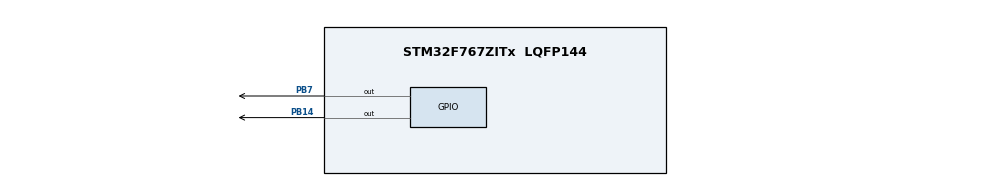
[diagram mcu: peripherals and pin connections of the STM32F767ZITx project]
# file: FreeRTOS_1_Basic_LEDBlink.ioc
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FREERTOS.Tasks01=blinkLEDBlue,24,128,StartBlinkLEDBlue,Default,NULL,Dynamic,NULL,NULL;blinkLEDRed,16,128,StartBlinkLEDRed,Default,NULL,Dynamic,NULL,NULL
Mcu.Family=STM32F7
Mcu.Name=STM32F767ZITx
Mcu.Package=LQFP144
NVIC.PriorityGroup=NVIC_PRIORITYGROUP_4
NVIC.TIM2_IRQn=true\:15\:0\:false\:false\:true\:false\:false\:true\:true
NVIC.TimeBase=TIM2_IRQn
NVIC.TimeBaseIP=TIM2
PA13.Mode=Serial_Wire
PA13.Signal=SYS_JTMS-SWDIO
PA14.Mode=Serial_Wire
PA14.Signal=SYS_JTCK-SWCLK
PB14.Signal=GPIO_Output
PB7.Signal=GPIO_Output
ProjectManager.HeapSize=0x200
ProjectManager.StackSize=0x400
ProjectManager.TargetToolchain=CMake
RCC.HSE_VALUE=25000000
RCC.HSI_VALUE=16000000
RCC.LSE_VALUE=32768
RCC.USBFreq_Value=96000000
RCC.VCOOutputFreq_Value=192000000
VP_FREERTOS_VS_CMSIS_V2.Mode=CMSIS_V2
VP_SYS_VS_tim2.Mode=TIM2
board=custom

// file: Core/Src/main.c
/* USER CODE BEGIN Header */
/**
  * @file           : main.c
  * @brief          : Main program body
  ******************************************************************************
  * @author         : Jabed-Akhtar
  * @date           : 13.03.2022
  ******************************************************************************
  * Description:
  *		- LED: PB7(Blue) and PB14(Red) (for testing purpose)
  *		- freeRTOS:
  *			|- thread1: blinkLEDBlueHandle -> thread to blink BlueLED every 500ms
  *				-> task is programmed inside StartBlinkLEDBlue(void)
  *			|- thread2: blinkLEDRed -> thread to blink RedLED every 600ms
  *				-> task is programmed inside StartBlinkLEDRed(void)
  *******************************************************************************/

/* USER CODE END Header */
#include "main.h"
#include "cmsis_os.h"

/* Definitions for blinkLEDBlue */
osThreadId_t blinkLEDBlueHandle;
const osThreadAttr_t blinkLEDBlue_attributes = {
  .name = "blinkLEDBlue",
  .stack_size = 128 * 4,
  .priority = (osPriority_t) osPriorityNormal,
};
/* Definitions for blinkLEDRed */
osThreadId_t blinkLEDRedHandle;
const osThreadAttr_t blinkLEDRed_attributes = {
  .name = "blinkLEDRed",
  .stack_size = 128 * 4,
  .priority = (osPriority_t) osPriorityBelowNormal,
};

void SystemClock_Config(void);
static void MX_GPIO_Init(void);
void StartBlinkLEDBlue(void *argument);
void StartBlinkLEDRed(void *argument);

int main(void)
{

  /* MCU Configuration--------------------------------------------------------*/

  /* Reset of all peripherals, Initializes the Flash interface and the Systick. */
  HAL_Init();

  /* Configure the system clock */
  SystemClock_Config();

  /* Initialize all configured peripherals */
  MX_GPIO_Init();

  /* Init scheduler */
  osKernelInitialize();

  /* Create the thread(s) */
  /* creation of blinkLEDBlue */
  blinkLEDBlueHandle = osThreadNew(StartBlinkLEDBlue, NULL, &blinkLEDBlue_attributes);

  /* creation of blinkLEDRed */
  blinkLEDRedHandle = osThreadNew(StartBlinkLEDRed, NULL, &blinkLEDRed_attributes);

  /* Start scheduler */
  osKernelStart();

  /* We should never get here as control is now taken by the scheduler */

  /* Infinite loop */
  while (1)
  {

  }
}

void SystemClock_Config(void)
{
  RCC_OscInitTypeDef RCC_OscInitStruct = {0};
  RCC_ClkInitTypeDef RCC_ClkInitStruct = {0};

  /** Configure the main internal regulator output voltage
  */
  __HAL_RCC_PWR_CLK_ENABLE();
  __HAL_PWR_VOLTAGESCALING_CONFIG(PWR_REGULATOR_VOLTAGE_SCALE3);

  /** Initializes the RCC Oscillators according to the specified parameters
  * in the RCC_OscInitTypeDef structure.
  */
  RCC_OscInitStruct.OscillatorType = RCC_OSCILLATORTYPE_HSI;
  RCC_OscInitStruct.HSIState = RCC_HSI_ON;
  RCC_OscInitStruct.HSICalibrationValue = RCC_HSICALIBRATION_DEFAULT;
  RCC_OscInitStruct.PLL.PLLState = RCC_PLL_NONE;
  if (HAL_RCC_OscConfig(&RCC_OscInitStruct) != HAL_OK)
  {
    Error_Handler();
  }

  /** Initializes the CPU, AHB and APB buses clocks
  */
  RCC_ClkInitStruct.ClockType = RCC_CLOCKTYPE_HCLK|RCC_CLOCKTYPE_SYSCLK
                              |RCC_CLOCKTYPE_PCLK1|RCC_CLOCKTYPE_PCLK2;
  RCC_ClkInitStruct.SYSCLKSource = RCC_SYSCLKSOURCE_HSI;
  RCC_ClkInitStruct.AHBCLKDivider = RCC_SYSCLK_DIV1;
  RCC_ClkInitStruct.APB1CLKDivider = RCC_HCLK_DIV1;
  RCC_ClkInitStruct.APB2CLKDivider = RCC_HCLK_DIV1;

  if (HAL_RCC_ClockConfig(&RCC_ClkInitStruct, FLASH_LATENCY_0) != HAL_OK)
  {
    Error_Handler();
  }
}

static void MX_GPIO_Init(void)
{
  GPIO_InitTypeDef GPIO_InitStruct = {0};

  /* GPIO Ports Clock Enable */
  __HAL_RCC_GPIOB_CLK_ENABLE();
  __HAL_RCC_GPIOA_CLK_ENABLE();

  /*Configure GPIO pin Output Level */
  HAL_GPIO_WritePin(GPIOB, GPIO_PIN_14|GPIO_PIN_7, GPIO_PIN_RESET);

  /*Configure GPIO pins : PB14 PB7 */
  GPIO_InitStruct.Pin = GPIO_PIN_14|GPIO_PIN_7;
  GPIO_InitStruct.Mode = GPIO_MODE_OUTPUT_PP;
  GPIO_InitStruct.Pull = GPIO_NOPULL;
  GPIO_InitStruct.Speed = GPIO_SPEED_FREQ_LOW;
  HAL_GPIO_Init(GPIOB, &GPIO_InitStruct);

}

void StartBlinkLEDBlue(void *argument)
{
  /* USER CODE BEGIN 5 */
  /* Infinite loop */
  for(;;)
  {
	  GPIOB->BSRR |= (1<<7); // set pin PB7 in register GPIOx_BSRR
    osDelay(500);
    GPIOB->BSRR |= ((1<<7)<<16); // reset pin PB7 in register GPIOx_BSRR
    osDelay(500);
  }
  // In case the sw accidently exit from task loop
  osThreadTerminate(NULL);
  /* USER CODE END 5 */
}

void StartBlinkLEDRed(void *argument)
{
  /* USER CODE BEGIN StartBlinkLEDRed */
  /* Infinite loop */
  for(;;)
  {
	  GPIOB->BSRR |= (1<<14); // set pin PB14 in register GPIOx_BSRR
    osDelay(600);
    GPIOB->BSRR |= ((1<<14)<<16); // reset pin PB14 in register GPIOx_BSRR
    osDelay(600);
    osThreadTerminate(NULL);
  }
  /* USER CODE END StartBlinkLEDRed */
}

void HAL_TIM_PeriodElapsedCallback(TIM_HandleTypeDef *htim)
{
  if (htim->Instance == TIM2) {
    HAL_IncTick();
  }
}

void Error_Handler(void)
{
  __disable_irq();
  while (1)
  {
  }
}
